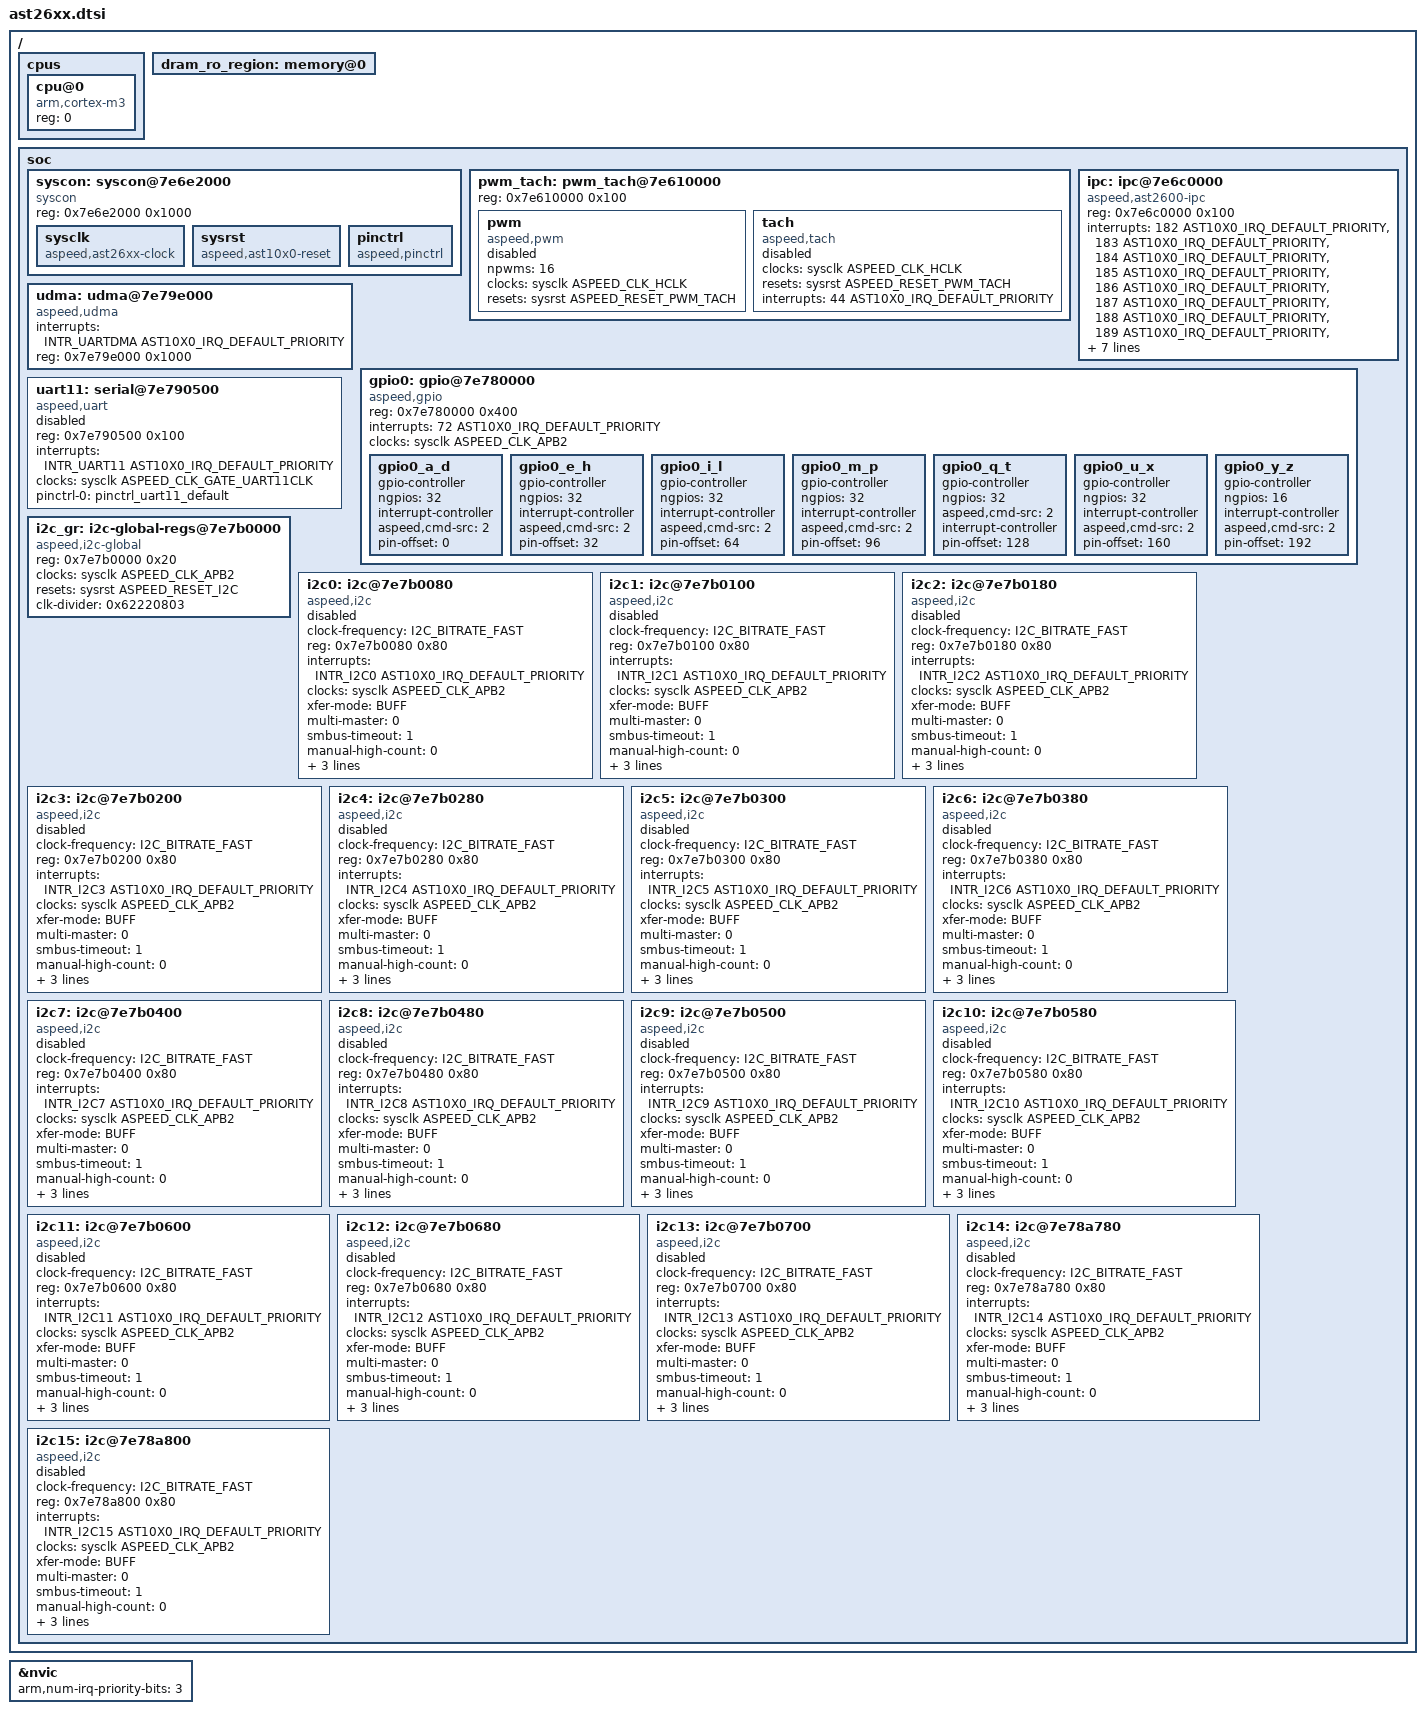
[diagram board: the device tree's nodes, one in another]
/*
 * SPDX-License-Identifier: Apache-2.0
 *
 * Copyright (c) 2021 ASPEED Technology Inc.
 */

#include <arm/armv7-m.dtsi>
#include <mem.h>
#include <aspeed/ast10x0-irq.h>
#include <zephyr/dt-bindings/clock/ast26xx_clock.h>
#include <zephyr/dt-bindings/reset/ast26xx_reset.h>
#include <zephyr/dt-bindings/i2c/i2c.h>
#include <zephyr/dt-bindings/pinctrl/ast26xx-pinctrl-groups.h>

/ {
	cpus {
		#address-cells = <1>;
		#size-cells = <0>;

		cpu@0 {
			device_type = "cpu";
			compatible = "arm,cortex-m3";
			reg = <0>;
		};
	};

	dram_ro_region: memory@0 {
		device_type = "memory";
	};

	soc {
		syscon: syscon@7e6e2000 {
			compatible = "syscon";
			reg = <0x7e6e2000 0x1000>;
			sysclk: sysclk {
				compatible = "aspeed,ast26xx-clock";
				#clock-cells = <1>;
			};

			sysrst: sysrst {
				compatible = "aspeed,ast10x0-reset";
				#reset-cells = <1>;
			};

			pinctrl: pinctrl {
				compatible = "aspeed,pinctrl";
			};
		};

		pwm_tach: pwm_tach@7e610000 {
			reg = <0x7e610000 0x100>;
			pwm: pwm {
				compatible = "aspeed,pwm";
				#pwm-cells = <3>;
				npwms = <16>;
				clocks = <&sysclk ASPEED_CLK_HCLK>;
				resets = <&sysrst ASPEED_RESET_PWM_TACH>;
				status = "disabled";
			};
			tach: tach {
				compatible = "aspeed,tach";
				#address-cells = <1>;
				#size-cells = <0>;
				clocks = <&sysclk ASPEED_CLK_HCLK>;
				resets = <&sysrst ASPEED_RESET_PWM_TACH>;
				interrupts = <44 AST10X0_IRQ_DEFAULT_PRIORITY>;
				status = "disabled";
			};
		};

		ipc: ipc@7e6c0000 {
			compatible = "aspeed,ast2600-ipc";
			reg = <0x7e6c0000 0x100>;
			interrupts = <182 AST10X0_IRQ_DEFAULT_PRIORITY>,
				     <183 AST10X0_IRQ_DEFAULT_PRIORITY>,
				     <184 AST10X0_IRQ_DEFAULT_PRIORITY>,
				     <185 AST10X0_IRQ_DEFAULT_PRIORITY>,
				     <186 AST10X0_IRQ_DEFAULT_PRIORITY>,
				     <187 AST10X0_IRQ_DEFAULT_PRIORITY>,
				     <188 AST10X0_IRQ_DEFAULT_PRIORITY>,
				     <189 AST10X0_IRQ_DEFAULT_PRIORITY>,
				     <190 AST10X0_IRQ_DEFAULT_PRIORITY>,
				     <191 AST10X0_IRQ_DEFAULT_PRIORITY>,
				     <192 AST10X0_IRQ_DEFAULT_PRIORITY>,
				     <193 AST10X0_IRQ_DEFAULT_PRIORITY>,
				     <194 AST10X0_IRQ_DEFAULT_PRIORITY>,
				     <195 AST10X0_IRQ_DEFAULT_PRIORITY>,
				     <196 AST10X0_IRQ_DEFAULT_PRIORITY>;
		};

		udma: udma@7e79e000 {
			compatible = "aspeed,udma";
			interrupts = <INTR_UARTDMA AST10X0_IRQ_DEFAULT_PRIORITY>;
			reg = <0x7e79e000 0x1000>;
		};

		gpio0: gpio@7e780000 {
			compatible = "aspeed,gpio";
			reg = <0x7e780000 0x400>;
			interrupts = <72 AST10X0_IRQ_DEFAULT_PRIORITY>;
			clocks = <&sysclk ASPEED_CLK_APB2>;
			gpio0_a_d: gpio0_a_d {
				#gpio-cells = <2>;
				gpio-controller;
				ngpios = <32>;
				interrupt-controller;
				#interrupt-cells = <2>;
				aspeed,cmd-src = <2>;
				pin-offset = <0>;
			};

			gpio0_e_h: gpio0_e_h {
				#gpio-cells = <2>;
				gpio-controller;
				ngpios = <32>;
				interrupt-controller;
				#interrupt-cells = <2>;
				aspeed,cmd-src = <2>;
				pin-offset = <32>;
			};

			gpio0_i_l: gpio0_i_l {
				#gpio-cells = <2>;
				gpio-controller;
				ngpios = <32>;
				interrupt-controller;
				#interrupt-cells = <2>;
				aspeed,cmd-src = <2>;
				pin-offset = <64>;
			};

			gpio0_m_p: gpio0_m_p {
				#gpio-cells = <2>;
				gpio-controller;
				ngpios = <32>;
				interrupt-controller;
				#interrupt-cells = <2>;
				aspeed,cmd-src = <2>;
				pin-offset = <96>;
			};

			gpio0_q_t: gpio0_q_t {
				#gpio-cells = <2>;
				gpio-controller;
				ngpios = <32>;
				aspeed,cmd-src = <2>;
				interrupt-controller;
				#interrupt-cells = <2>;
				pin-offset = <128>;
			};

			gpio0_u_x: gpio0_u_x {
				#gpio-cells = <2>;
				gpio-controller;
				ngpios = <32>;
				interrupt-controller;
				#interrupt-cells = <2>;
				aspeed,cmd-src = <2>;
				pin-offset = <160>;
			};

			gpio0_y_z: gpio0_y_z {
				#gpio-cells = <2>;
				gpio-controller;
				ngpios = <16>;
				interrupt-controller;
				#interrupt-cells = <2>;
				aspeed,cmd-src = <2>;
				pin-offset = <192>;
			};
		};

		uart11: serial@7e790500 {
			compatible = "aspeed,uart";
			reg = <0x7e790500 0x100>;
			interrupts = <INTR_UART11 AST10X0_IRQ_DEFAULT_PRIORITY>;
			clocks = <&sysclk ASPEED_CLK_GATE_UART11CLK>;
			status = "disabled";
			pinctrl-0 = <pinctrl_uart11_default>;
			pinctrl-names = "default";
		};

		i2c_gr: i2c-global-regs@7e7b0000 {
			compatible = "aspeed,i2c-global";
			#address-cells = <1>;
			#size-cells = <0>;
			reg = <0x7e7b0000 0x20>;
			clocks = <&sysclk ASPEED_CLK_APB2>;
			resets = <&sysrst ASPEED_RESET_I2C>;
			clk-divider = <0x62220803>;
		};

		i2c0: i2c@7e7b0080 {
			compatible = "aspeed,i2c";
			clock-frequency = <I2C_BITRATE_FAST>;
			#address-cells = <1>;
			#size-cells = <0>;
			reg = <0x7e7b0080 0x80>;
			interrupts = <INTR_I2C0 AST10X0_IRQ_DEFAULT_PRIORITY>;
			clocks = <&sysclk ASPEED_CLK_APB2>;
			xfer-mode = "BUFF";
			multi-master = <0>;
			smbus-timeout = <1>;
			manual-high-count = <0>;
			manual-low-count = <0>;
			manual-sda-delay = <0>;
			pinctrl-0 = <pinctrl_i2c0_default>;
			pinctrl-names = "default";
			status = "disabled";
		};

		i2c1: i2c@7e7b0100 {
			compatible = "aspeed,i2c";
			clock-frequency = <I2C_BITRATE_FAST>;
			#address-cells = <1>;
			#size-cells = <0>;
			reg = <0x7e7b0100 0x80>;
			interrupts = <INTR_I2C1 AST10X0_IRQ_DEFAULT_PRIORITY>;
			clocks = <&sysclk ASPEED_CLK_APB2>;
			xfer-mode = "BUFF";
			multi-master = <0>;
			smbus-timeout = <1>;
			manual-high-count = <0>;
			manual-low-count = <0>;
			manual-sda-delay = <0>;
			pinctrl-0 = <pinctrl_i2c1_default>;
			pinctrl-names = "default";
			status = "disabled";
		};

		i2c2: i2c@7e7b0180 {
			compatible = "aspeed,i2c";
			clock-frequency = <I2C_BITRATE_FAST>;
			#address-cells = <1>;
			#size-cells = <0>;
			reg = <0x7e7b0180 0x80>;
			interrupts = <INTR_I2C2 AST10X0_IRQ_DEFAULT_PRIORITY>;
			clocks = <&sysclk ASPEED_CLK_APB2>;
			xfer-mode = "BUFF";
			multi-master = <0>;
			smbus-timeout = <1>;
			manual-high-count = <0>;
			manual-low-count = <0>;
			manual-sda-delay = <0>;
			pinctrl-0 = <pinctrl_i2c2_default>;
			pinctrl-names = "default";
			status = "disabled";
		};

		i2c3: i2c@7e7b0200 {
			compatible = "aspeed,i2c";
			clock-frequency = <I2C_BITRATE_FAST>;
			#address-cells = <1>;
			#size-cells = <0>;
			reg = <0x7e7b0200 0x80>;
			interrupts = <INTR_I2C3 AST10X0_IRQ_DEFAULT_PRIORITY>;
			clocks = <&sysclk ASPEED_CLK_APB2>;
			xfer-mode = "BUFF";
			multi-master = <0>;
			smbus-timeout = <1>;
			manual-high-count = <0>;
			manual-low-count = <0>;
			manual-sda-delay = <0>;
			pinctrl-0 = <pinctrl_i2c3_default>;
			pinctrl-names = "default";
			status = "disabled";
		};

		i2c4: i2c@7e7b0280 {
			compatible = "aspeed,i2c";
			clock-frequency = <I2C_BITRATE_FAST>;
			#address-cells = <1>;
			#size-cells = <0>;
			reg = <0x7e7b0280 0x80>;
			interrupts = <INTR_I2C4 AST10X0_IRQ_DEFAULT_PRIORITY>;
			clocks = <&sysclk ASPEED_CLK_APB2>;
			xfer-mode = "BUFF";
			multi-master = <0>;
			smbus-timeout = <1>;
			manual-high-count = <0>;
			manual-low-count = <0>;
			manual-sda-delay = <0>;
			pinctrl-0 = <pinctrl_i2c4_default>;
			pinctrl-names = "default";
			status = "disabled";
		};

		i2c5: i2c@7e7b0300 {
			compatible = "aspeed,i2c";
			clock-frequency = <I2C_BITRATE_FAST>;
			#address-cells = <1>;
			#size-cells = <0>;
			reg = <0x7e7b0300 0x80>;
			interrupts = <INTR_I2C5 AST10X0_IRQ_DEFAULT_PRIORITY>;
			clocks = <&sysclk ASPEED_CLK_APB2>;
			xfer-mode = "BUFF";
			multi-master = <0>;
			smbus-timeout = <1>;
			manual-high-count = <0>;
			manual-low-count = <0>;
			manual-sda-delay = <0>;
			pinctrl-0 = <pinctrl_i2c5_default>;
			pinctrl-names = "default";
			status = "disabled";
		};

		i2c6: i2c@7e7b0380 {
			compatible = "aspeed,i2c";
			clock-frequency = <I2C_BITRATE_FAST>;
			#address-cells = <1>;
			#size-cells = <0>;
			reg = <0x7e7b0380 0x80>;
			interrupts = <INTR_I2C6 AST10X0_IRQ_DEFAULT_PRIORITY>;
			clocks = <&sysclk ASPEED_CLK_APB2>;
			xfer-mode = "BUFF";
			multi-master = <0>;
			smbus-timeout = <1>;
			manual-high-count = <0>;
			manual-low-count = <0>;
			manual-sda-delay = <0>;
			pinctrl-0 = <pinctrl_i2c6_default>;
			pinctrl-names = "default";
			status = "disabled";
		};

		i2c7: i2c@7e7b0400 {
			compatible = "aspeed,i2c";
			clock-frequency = <I2C_BITRATE_FAST>;
			#address-cells = <1>;
			#size-cells = <0>;
			reg = <0x7e7b0400 0x80>;
			interrupts = <INTR_I2C7 AST10X0_IRQ_DEFAULT_PRIORITY>;
			clocks = <&sysclk ASPEED_CLK_APB2>;
			xfer-mode = "BUFF";
			multi-master = <0>;
			smbus-timeout = <1>;
			manual-high-count = <0>;
			manual-low-count = <0>;
			manual-sda-delay = <0>;
			pinctrl-0 = <pinctrl_i2c7_default>;
			pinctrl-names = "default";
			status = "disabled";
		};

		i2c8: i2c@7e7b0480 {
			compatible = "aspeed,i2c";
			clock-frequency = <I2C_BITRATE_FAST>;
			#address-cells = <1>;
			#size-cells = <0>;
			reg = <0x7e7b0480 0x80>;
			interrupts = <INTR_I2C8 AST10X0_IRQ_DEFAULT_PRIORITY>;
			clocks = <&sysclk ASPEED_CLK_APB2>;
			xfer-mode = "BUFF";
			multi-master = <0>;
			smbus-timeout = <1>;
			manual-high-count = <0>;
			manual-low-count = <0>;
			manual-sda-delay = <0>;
			pinctrl-0 = <pinctrl_i2c8_default>;
			pinctrl-names = "default";
			status = "disabled";
		};

		i2c9: i2c@7e7b0500 {
			compatible = "aspeed,i2c";
			clock-frequency = <I2C_BITRATE_FAST>;
			#address-cells = <1>;
			#size-cells = <0>;
			reg = <0x7e7b0500 0x80>;
			interrupts = <INTR_I2C9 AST10X0_IRQ_DEFAULT_PRIORITY>;
			clocks = <&sysclk ASPEED_CLK_APB2>;
			xfer-mode = "BUFF";
			multi-master = <0>;
			smbus-timeout = <1>;
			manual-high-count = <0>;
			manual-low-count = <0>;
			manual-sda-delay = <0>;
			pinctrl-0 = <pinctrl_i2c9_default>;
			pinctrl-names = "default";
			status = "disabled";
		};

		i2c10: i2c@7e7b0580 {
			compatible = "aspeed,i2c";
			clock-frequency = <I2C_BITRATE_FAST>;
			#address-cells = <1>;
			#size-cells = <0>;
			reg = <0x7e7b0580 0x80>;
			interrupts = <INTR_I2C10 AST10X0_IRQ_DEFAULT_PRIORITY>;
			clocks = <&sysclk ASPEED_CLK_APB2>;
			xfer-mode = "BUFF";
			multi-master = <0>;
			smbus-timeout = <1>;
			manual-high-count = <0>;
			manual-low-count = <0>;
			manual-sda-delay = <0>;
			pinctrl-0 = <pinctrl_i2c10_default>;
			pinctrl-names = "default";
			status = "disabled";
		};

		i2c11: i2c@7e7b0600 {
			compatible = "aspeed,i2c";
			clock-frequency = <I2C_BITRATE_FAST>;
			#address-cells = <1>;
			#size-cells = <0>;
			reg = <0x7e7b0600 0x80>;
			interrupts = <INTR_I2C11 AST10X0_IRQ_DEFAULT_PRIORITY>;
			clocks = <&sysclk ASPEED_CLK_APB2>;
			xfer-mode = "BUFF";
			multi-master = <0>;
			smbus-timeout = <1>;
			manual-high-count = <0>;
			manual-low-count = <0>;
			manual-sda-delay = <0>;
			pinctrl-0 = <pinctrl_i2c11_default>;
			pinctrl-names = "default";
			status = "disabled";
		};

		i2c12: i2c@7e7b0680 {
			compatible = "aspeed,i2c";
			clock-frequency = <I2C_BITRATE_FAST>;
			#address-cells = <1>;
			#size-cells = <0>;
			reg = <0x7e7b0680 0x80>;
			interrupts = <INTR_I2C12 AST10X0_IRQ_DEFAULT_PRIORITY>;
			clocks = <&sysclk ASPEED_CLK_APB2>;
			xfer-mode = "BUFF";
			multi-master = <0>;
			smbus-timeout = <1>;
			manual-high-count = <0>;
			manual-low-count = <0>;
			manual-sda-delay = <0>;
			pinctrl-0 = <pinctrl_i2c12_default>;
			pinctrl-names = "default";
			status = "disabled";
		};

		i2c13: i2c@7e7b0700 {
			compatible = "aspeed,i2c";
			clock-frequency = <I2C_BITRATE_FAST>;
			#address-cells = <1>;
			#size-cells = <0>;
			reg = <0x7e7b0700 0x80>;
			interrupts = <INTR_I2C13 AST10X0_IRQ_DEFAULT_PRIORITY>;
			clocks = <&sysclk ASPEED_CLK_APB2>;
			xfer-mode = "BUFF";
			multi-master = <0>;
			smbus-timeout = <1>;
			manual-high-count = <0>;
			manual-low-count = <0>;
			manual-sda-delay = <0>;
			pinctrl-0 = <pinctrl_i2c13_default>;
			pinctrl-names = "default";
			status = "disabled";
		};

		i2c14: i2c@7e78a780 {
			compatible = "aspeed,i2c";
			clock-frequency = <I2C_BITRATE_FAST>;
			#address-cells = <1>;
			#size-cells = <0>;
			reg = <0x7e78a780 0x80>;
			interrupts = <INTR_I2C14 AST10X0_IRQ_DEFAULT_PRIORITY>;
			clocks = <&sysclk ASPEED_CLK_APB2>;
			xfer-mode = "BUFF";
			multi-master = <0>;
			smbus-timeout = <1>;
			manual-high-count = <0>;
			manual-low-count = <0>;
			manual-sda-delay = <0>;
			pinctrl-0 = <pinctrl_i2c14_default>;
			pinctrl-names = "default";
			status = "disabled";
		};

		i2c15: i2c@7e78a800 {
			compatible = "aspeed,i2c";
			clock-frequency = <I2C_BITRATE_FAST>;
			#address-cells = <1>;
			#size-cells = <0>;
			reg = <0x7e78a800 0x80>;
			interrupts = <INTR_I2C15 AST10X0_IRQ_DEFAULT_PRIORITY>;
			clocks = <&sysclk ASPEED_CLK_APB2>;
			xfer-mode = "BUFF";
			multi-master = <0>;
			smbus-timeout = <1>;
			manual-high-count = <0>;
			manual-low-count = <0>;
			manual-sda-delay = <0>;
			pinctrl-0 = <pinctrl_i2c15_default>;
			pinctrl-names = "default";
			status = "disabled";
		};
	};
};

&nvic {
	arm,num-irq-priority-bits = <3>;
};

#include "ast26xx-pinctrl.dtsi"
